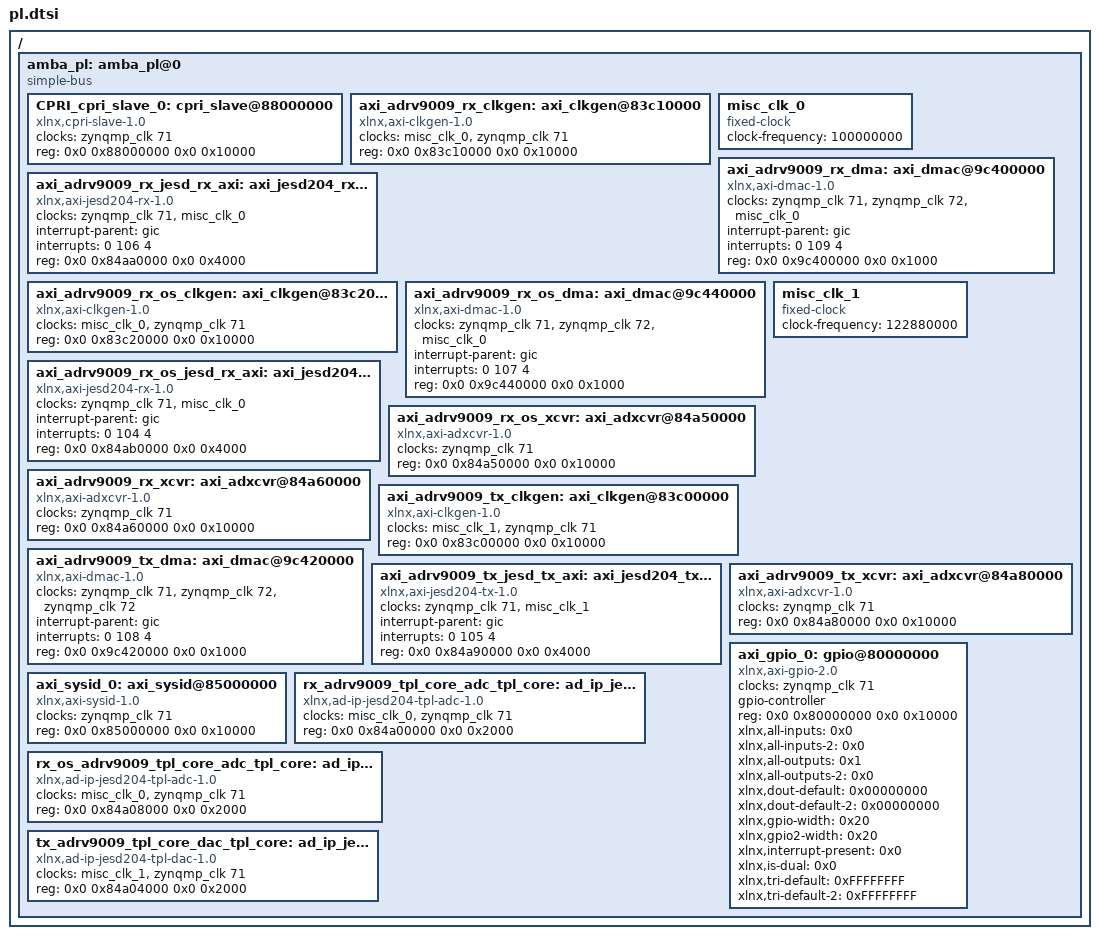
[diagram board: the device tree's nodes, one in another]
/*
 * CAUTION: This file is automatically generated by Xilinx.
 * Version:  
 * Today is: Tue Jan 30 08:12:52 2024
 */


/ {
	amba_pl: amba_pl@0 {
		#address-cells = <2>;
		#size-cells = <2>;
		compatible = "simple-bus";
		ranges ;
		CPRI_cpri_slave_0: cpri_slave@88000000 {
			clock-names = "s_axi_aclk";
			clocks = <&zynqmp_clk 71>;
			compatible = "xlnx,cpri-slave-1.0";
			reg = <0x0 0x88000000 0x0 0x10000>;
		};
		axi_adrv9009_rx_clkgen: axi_clkgen@83c10000 {
			clock-names = "clk", "s_axi_aclk";
			clocks = <&misc_clk_0>, <&zynqmp_clk 71>;
			compatible = "xlnx,axi-clkgen-1.0";
			reg = <0x0 0x83c10000 0x0 0x10000>;
		};
		misc_clk_0: misc_clk_0 {
			#clock-cells = <0>;
			clock-frequency = <100000000>;
			compatible = "fixed-clock";
		};
		axi_adrv9009_rx_dma: axi_dmac@9c400000 {
			clock-names = "s_axi_aclk", "m_dest_axi_aclk", "fifo_wr_clk";
			clocks = <&zynqmp_clk 71>, <&zynqmp_clk 72>, <&misc_clk_0>;
			compatible = "xlnx,axi-dmac-1.0";
			interrupt-names = "irq";
			interrupt-parent = <&gic>;
			interrupts = <0 109 4>;
			reg = <0x0 0x9c400000 0x0 0x1000>;
		};
		axi_adrv9009_rx_jesd_rx_axi: axi_jesd204_rx@84aa0000 {
			clock-names = "s_axi_aclk", "core_clk";
			clocks = <&zynqmp_clk 71>, <&misc_clk_0>;
			compatible = "xlnx,axi-jesd204-rx-1.0";
			interrupt-names = "irq";
			interrupt-parent = <&gic>;
			interrupts = <0 106 4>;
			reg = <0x0 0x84aa0000 0x0 0x4000>;
		};
		axi_adrv9009_rx_os_clkgen: axi_clkgen@83c20000 {
			clock-names = "clk", "s_axi_aclk";
			clocks = <&misc_clk_0>, <&zynqmp_clk 71>;
			compatible = "xlnx,axi-clkgen-1.0";
			reg = <0x0 0x83c20000 0x0 0x10000>;
		};
		axi_adrv9009_rx_os_dma: axi_dmac@9c440000 {
			clock-names = "s_axi_aclk", "m_dest_axi_aclk", "fifo_wr_clk";
			clocks = <&zynqmp_clk 71>, <&zynqmp_clk 72>, <&misc_clk_0>;
			compatible = "xlnx,axi-dmac-1.0";
			interrupt-names = "irq";
			interrupt-parent = <&gic>;
			interrupts = <0 107 4>;
			reg = <0x0 0x9c440000 0x0 0x1000>;
		};
		axi_adrv9009_rx_os_jesd_rx_axi: axi_jesd204_rx@84ab0000 {
			clock-names = "s_axi_aclk", "core_clk";
			clocks = <&zynqmp_clk 71>, <&misc_clk_0>;
			compatible = "xlnx,axi-jesd204-rx-1.0";
			interrupt-names = "irq";
			interrupt-parent = <&gic>;
			interrupts = <0 104 4>;
			reg = <0x0 0x84ab0000 0x0 0x4000>;
		};
		axi_adrv9009_rx_os_xcvr: axi_adxcvr@84a50000 {
			clock-names = "s_axi_aclk";
			clocks = <&zynqmp_clk 71>;
			compatible = "xlnx,axi-adxcvr-1.0";
			reg = <0x0 0x84a50000 0x0 0x10000>;
		};
		axi_adrv9009_rx_xcvr: axi_adxcvr@84a60000 {
			clock-names = "s_axi_aclk";
			clocks = <&zynqmp_clk 71>;
			compatible = "xlnx,axi-adxcvr-1.0";
			reg = <0x0 0x84a60000 0x0 0x10000>;
		};
		axi_adrv9009_tx_clkgen: axi_clkgen@83c00000 {
			clock-names = "clk", "s_axi_aclk";
			clocks = <&misc_clk_1>, <&zynqmp_clk 71>;
			compatible = "xlnx,axi-clkgen-1.0";
			reg = <0x0 0x83c00000 0x0 0x10000>;
		};
		misc_clk_1: misc_clk_1 {
			#clock-cells = <0>;
			clock-frequency = <122880000>;
			compatible = "fixed-clock";
		};
		axi_adrv9009_tx_dma: axi_dmac@9c420000 {
			clock-names = "s_axi_aclk", "m_src_axi_aclk", "m_axis_aclk";
			clocks = <&zynqmp_clk 71>, <&zynqmp_clk 72>, <&zynqmp_clk 72>;
			compatible = "xlnx,axi-dmac-1.0";
			interrupt-names = "irq";
			interrupt-parent = <&gic>;
			interrupts = <0 108 4>;
			reg = <0x0 0x9c420000 0x0 0x1000>;
		};
		axi_adrv9009_tx_jesd_tx_axi: axi_jesd204_tx@84a90000 {
			clock-names = "s_axi_aclk", "core_clk";
			clocks = <&zynqmp_clk 71>, <&misc_clk_1>;
			compatible = "xlnx,axi-jesd204-tx-1.0";
			interrupt-names = "irq";
			interrupt-parent = <&gic>;
			interrupts = <0 105 4>;
			reg = <0x0 0x84a90000 0x0 0x4000>;
		};
		axi_adrv9009_tx_xcvr: axi_adxcvr@84a80000 {
			clock-names = "s_axi_aclk";
			clocks = <&zynqmp_clk 71>;
			compatible = "xlnx,axi-adxcvr-1.0";
			reg = <0x0 0x84a80000 0x0 0x10000>;
		};
		axi_gpio_0: gpio@80000000 {
			#gpio-cells = <3>;
			clock-names = "s_axi_aclk";
			clocks = <&zynqmp_clk 71>;
			compatible = "xlnx,axi-gpio-2.0", "xlnx,xps-gpio-1.00.a";
			gpio-controller ;
			reg = <0x0 0x80000000 0x0 0x10000>;
			xlnx,all-inputs = <0x0>;
			xlnx,all-inputs-2 = <0x0>;
			xlnx,all-outputs = <0x1>;
			xlnx,all-outputs-2 = <0x0>;
			xlnx,dout-default = <0x00000000>;
			xlnx,dout-default-2 = <0x00000000>;
			xlnx,gpio-width = <0x20>;
			xlnx,gpio2-width = <0x20>;
			xlnx,interrupt-present = <0x0>;
			xlnx,is-dual = <0x0>;
			xlnx,tri-default = <0xFFFFFFFF>;
			xlnx,tri-default-2 = <0xFFFFFFFF>;
		};
		axi_sysid_0: axi_sysid@85000000 {
			clock-names = "s_axi_aclk";
			clocks = <&zynqmp_clk 71>;
			compatible = "xlnx,axi-sysid-1.0";
			reg = <0x0 0x85000000 0x0 0x10000>;
		};
		rx_adrv9009_tpl_core_adc_tpl_core: ad_ip_jesd204_tpl_adc@84a00000 {
			clock-names = "link_clk", "s_axi_aclk";
			clocks = <&misc_clk_0>, <&zynqmp_clk 71>;
			compatible = "xlnx,ad-ip-jesd204-tpl-adc-1.0";
			reg = <0x0 0x84a00000 0x0 0x2000>;
		};
		rx_os_adrv9009_tpl_core_adc_tpl_core: ad_ip_jesd204_tpl_adc@84a08000 {
			clock-names = "link_clk", "s_axi_aclk";
			clocks = <&misc_clk_0>, <&zynqmp_clk 71>;
			compatible = "xlnx,ad-ip-jesd204-tpl-adc-1.0";
			reg = <0x0 0x84a08000 0x0 0x2000>;
		};
		tx_adrv9009_tpl_core_dac_tpl_core: ad_ip_jesd204_tpl_dac@84a04000 {
			clock-names = "link_clk", "s_axi_aclk";
			clocks = <&misc_clk_1>, <&zynqmp_clk 71>;
			compatible = "xlnx,ad-ip-jesd204-tpl-dac-1.0";
			reg = <0x0 0x84a04000 0x0 0x2000>;
		};
	};
};
/include/ "pl-delete-nodes-zynqmp-zcu102-rev10-adrv9009-jesd204-fsm.dtsi"
